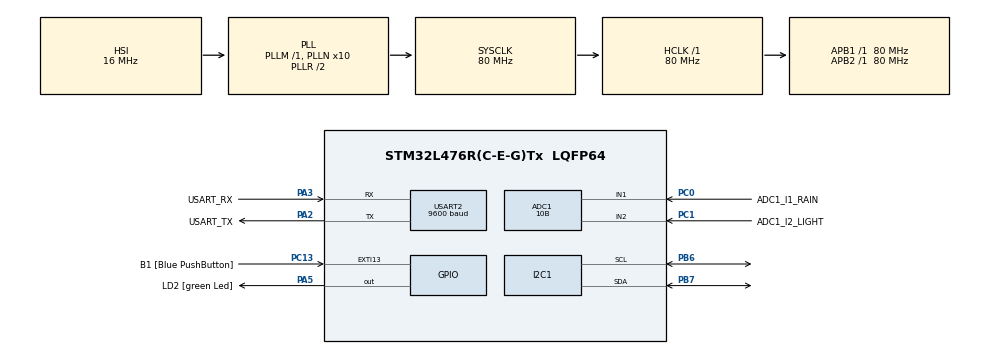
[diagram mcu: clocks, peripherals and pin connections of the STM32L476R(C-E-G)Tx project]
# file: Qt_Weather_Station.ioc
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Mcu.Family=STM32L4
PA2.GPIO_PuPd=GPIO_NOPULL
RCC.CortexFreq_Value=80000000
PH0-OSC_IN\ (PH0).Signal=RCC_OSC_IN
SH.ADCx_IN2.0=ADC1_IN2,IN2-Single-Ended
PA3.GPIO_PuPd=GPIO_NOPULL
PA2.GPIO_Speed=GPIO_SPEED_FREQ_VERY_HIGH
PC0.GPIO_Label=ADC1_I1_RAIN
PC15-OSC32_OUT\ (PC15).Mode=LSE-External-Oscillator
PC13.GPIO_Label=B1 [Blue PushButton]
PA3.GPIO_Speed=GPIO_SPEED_FREQ_VERY_HIGH
RCC.SYSCLKSource=RCC_SYSCLKSOURCE_PLLCLK
ProjectManager.StackSize=0x400
PB3\ (JTDO-TRACESWO).Signal=SYS_JTDO-SWO
PC14-OSC32_IN\ (PC14).Mode=LSE-External-Oscillator
PA14\ (JTCK-SWCLK).Signal=SYS_JTCK-SWCLK
RCC.HCLKFreq_Value=80000000
ADC1.Resolution=ADC_RESOLUTION_10B
RCC.APB2TimFreq_Value=80000000
PB6.Signal=I2C1_SCL
PB6.Mode=I2C
RCC.AHBFreq_Value=80000000
RCC.PREFETCH_ENABLE=1
ADC1.Channel-0\#ChannelRegularConversion=ADC_CHANNEL_1
RCC.HSE_VALUE=8000000
USART2.VirtualMode-Asynchronous=VM_ASYNC
PA5.GPIO_PuPd=GPIO_NOPULL
PC13.GPIO_PuPd=GPIO_NOPULL
PB7.Signal=I2C1_SDA
ADC1.SamplingTime-0\#ChannelRegularConversion=ADC_SAMPLETIME_640CYCLES_5
Mcu.Package=LQFP64
PA2.GPIO_Label=USART_TX
ADC1.OffsetNumber-1\#ChannelRegularConversion=ADC_OFFSET_NONE
SH.ADCx_IN1.0=ADC1_IN1,IN1-Single-Ended
RCC.APB1TimFreq_Value=80000000
PA13\ (JTMS-SWDIO).Signal=SYS_JTMS-SWDIO
PA3.Signal=USART2_RX
PA2.GPIO_Mode=GPIO_MODE_AF_PP
RCC.MSI_VALUE=4000000
RCC.PLLSourceVirtual=RCC_PLLSOURCE_HSI
PA14\ (JTCK-SWCLK).Mode=Serial_Wire
ADC1.Rank-0\#ChannelRegularConversion=1
ADC1.OffsetNumber-0\#ChannelRegularConversion=ADC_OFFSET_NONE
PC13.Signal=GPXTI13
PC15-OSC32_OUT\ (PC15).Signal=RCC_OSC32_OUT
PA14\ (JTCK-SWCLK).GPIO_Label=TCK
PB3\ (JTDO-TRACESWO).GPIO_Label=SWO
PC0.Signal=ADCx_IN1
USART2.BaudRate=9600
PH1-OSC_OUT\ (PH1).Signal=RCC_OSC_OUT
PA3.Mode=Asynchronous
ProjectManager.TargetToolchain=STM32CubeIDE
PA3.GPIO_Mode=GPIO_MODE_AF_PP
ADC1.Channel-1\#ChannelRegularConversion=ADC_CHANNEL_2
I2C1.Timing=0x10909CEC
RCC.USBFreq_Value=64000000
PA5.Signal=GPIO_Output
board=NUCLEO-L476RG
RCC.VCOOutputFreq_Value=160000000
RCC.APB2Freq_Value=80000000
PA5.GPIO_ModeDefaultOutputPP=GPIO_MODE_OUTPUT_PP
PA13\ (JTMS-SWDIO).GPIO_Label=TMS
RCC.ADCFreq_Value=64000000
PC1.GPIO_Label=ADC1_I2_LIGHT
ADC1.NbrOfConversion=2
Mcu.Name=STM32L476R(C-E-G)Tx
PA2.Signal=USART2_TX
PA13\ (JTMS-SWDIO).Mode=Serial_Wire
ADC1.SamplingTime-1\#ChannelRegularConversion=ADC_SAMPLETIME_640CYCLES_5
RCC.SYSCLKFreq_VALUE=80000000
ADC1.master=1
PA5.GPIO_Label=LD2 [green Led]
PC13.GPIO_ModeDefaultEXTI=GPIO_MODE_IT_FALLING
PC14-OSC32_IN\ (PC14).Signal=RCC_OSC32_IN
ADC1.Rank-1\#ChannelRegularConversion=2
PB7.Mode=I2C
ProjectManager.HeapSize=0x200
RCC.HSI_VALUE=16000000
PA5.GPIO_Speed=GPIO_SPEED_FREQ_LOW
NVIC.PriorityGroup=NVIC_PRIORITYGROUP_4
ADC1.NbrOfConversionFlag=1
RCC.PLLN=10
PA2.Mode=Asynchronous
RCC.APB1Freq_Value=80000000
PC1.Signal=ADCx_IN2
PA3.GPIO_Label=USART_RX

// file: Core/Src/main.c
/* USER CODE BEGIN Header */
/**
  ******************************************************************************
  * @file           : main.c
  * @brief          : Main program body
  ******************************************************************************
  * @attention
  *
  * <h2><center>&copy; Copyright (c) 2023 STMicroelectronics.
  * All rights reserved.</center></h2>
  *
  * This software component is licensed by ST under BSD 3-Clause license,
  * the "License"; You may not use this file except in compliance with the
  * License. You may obtain a copy of the License at:
  *                        opensource.org/licenses/BSD-3-Clause
  *
  ******************************************************************************
  */
/* USER CODE END Header */
#include "main.h"
#include "adc.h"
#include "i2c.h"
#include "usart.h"
#include "gpio.h"

/* USER CODE BEGIN Includes */
#include "bmpX80.h"
#include "weather_station.h"
#include "stdio.h"
/* USER CODE END Includes */

/* USER CODE BEGIN PTD */

WS_DataTypedef hwsdata;
/* USER CODE END PTD */

/* USER CODE BEGIN PD */
int _write(int* file, char* ptr, int len)
{
	HAL_UART_Transmit(&huart2, (uint8_t*)ptr, len, HAL_MAX_DELAY);
	return len;
}
/* USER CODE END PD */

void SystemClock_Config(void);

int main(void)
{
  /* USER CODE BEGIN 1 */
//	BMP280_CompensationParametersType bmp;
  /* USER CODE END 1 */

  /* MCU Configuration--------------------------------------------------------*/

  /* Reset of all peripherals, Initializes the Flash interface and the Systick. */
  HAL_Init();

  /* Configure the system clock */
  SystemClock_Config();

  /* Initialize all configured peripherals */
  MX_GPIO_Init();
  MX_USART2_UART_Init();
  MX_I2C1_Init();
  MX_ADC1_Init();
  /* USER CODE BEGIN 2 */

  HAL_ADCEx_Calibration_Start(&hadc1, ADC_SINGLE_ENDED);
  BMP280_init(BMP280_TEMP_16b, BMP280_PRESS_STANDARD, BMP280_MODE_FORCED);

  /* USER CODE END 2 */

  /* Infinite loop */
  /* USER CODE BEGIN WHILE */
  while (1)
  {
	  WS_collectData(&hwsdata);
	  char msg[50];
	  WS_createStr(&hwsdata, msg);
	  printf("%s", msg);
	  HAL_Delay(1000);

    /* USER CODE END WHILE */

  }
}

void SystemClock_Config(void)
{
  RCC_OscInitTypeDef RCC_OscInitStruct = {0};
  RCC_ClkInitTypeDef RCC_ClkInitStruct = {0};
  RCC_PeriphCLKInitTypeDef PeriphClkInit = {0};

  /** Initializes the RCC Oscillators according to the specified parameters
  * in the RCC_OscInitTypeDef structure.
  */
  RCC_OscInitStruct.OscillatorType = RCC_OSCILLATORTYPE_HSI;
  RCC_OscInitStruct.HSIState = RCC_HSI_ON;
  RCC_OscInitStruct.HSICalibrationValue = RCC_HSICALIBRATION_DEFAULT;
  RCC_OscInitStruct.PLL.PLLState = RCC_PLL_ON;
  RCC_OscInitStruct.PLL.PLLSource = RCC_PLLSOURCE_HSI;
  RCC_OscInitStruct.PLL.PLLM = 1;
  RCC_OscInitStruct.PLL.PLLN = 10;
  RCC_OscInitStruct.PLL.PLLP = RCC_PLLP_DIV7;
  RCC_OscInitStruct.PLL.PLLQ = RCC_PLLQ_DIV2;
  RCC_OscInitStruct.PLL.PLLR = RCC_PLLR_DIV2;
  if (HAL_RCC_OscConfig(&RCC_OscInitStruct) != HAL_OK)
  {
    Error_Handler();
  }
  /** Initializes the CPU, AHB and APB buses clocks
  */
  RCC_ClkInitStruct.ClockType = RCC_CLOCKTYPE_HCLK|RCC_CLOCKTYPE_SYSCLK
                              |RCC_CLOCKTYPE_PCLK1|RCC_CLOCKTYPE_PCLK2;
  RCC_ClkInitStruct.SYSCLKSource = RCC_SYSCLKSOURCE_PLLCLK;
  RCC_ClkInitStruct.AHBCLKDivider = RCC_SYSCLK_DIV1;
  RCC_ClkInitStruct.APB1CLKDivider = RCC_HCLK_DIV1;
  RCC_ClkInitStruct.APB2CLKDivider = RCC_HCLK_DIV1;

  if (HAL_RCC_ClockConfig(&RCC_ClkInitStruct, FLASH_LATENCY_4) != HAL_OK)
  {
    Error_Handler();
  }
  PeriphClkInit.PeriphClockSelection = RCC_PERIPHCLK_USART2|RCC_PERIPHCLK_I2C1
                              |RCC_PERIPHCLK_ADC;
  PeriphClkInit.Usart2ClockSelection = RCC_USART2CLKSOURCE_PCLK1;
  PeriphClkInit.I2c1ClockSelection = RCC_I2C1CLKSOURCE_PCLK1;
  PeriphClkInit.AdcClockSelection = RCC_ADCCLKSOURCE_PLLSAI1;
  PeriphClkInit.PLLSAI1.PLLSAI1Source = RCC_PLLSOURCE_HSI;
  PeriphClkInit.PLLSAI1.PLLSAI1M = 1;
  PeriphClkInit.PLLSAI1.PLLSAI1N = 8;
  PeriphClkInit.PLLSAI1.PLLSAI1P = RCC_PLLP_DIV7;
  PeriphClkInit.PLLSAI1.PLLSAI1Q = RCC_PLLQ_DIV2;
  PeriphClkInit.PLLSAI1.PLLSAI1R = RCC_PLLR_DIV4;
  PeriphClkInit.PLLSAI1.PLLSAI1ClockOut = RCC_PLLSAI1_ADC1CLK;
  if (HAL_RCCEx_PeriphCLKConfig(&PeriphClkInit) != HAL_OK)
  {
    Error_Handler();
  }
  /** Configure the main internal regulator output voltage
  */
  if (HAL_PWREx_ControlVoltageScaling(PWR_REGULATOR_VOLTAGE_SCALE1) != HAL_OK)
  {
    Error_Handler();
  }
}

void Error_Handler(void)
{
  __disable_irq();
  while (1)
  {
  }
}

/************************ (C) COPYRIGHT STMicroelectronics *****END OF FILE****/
